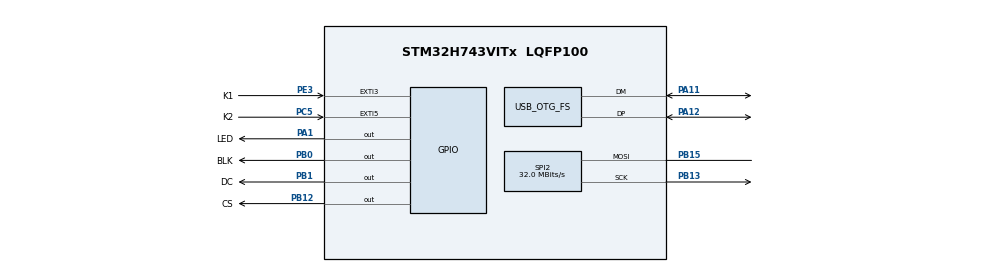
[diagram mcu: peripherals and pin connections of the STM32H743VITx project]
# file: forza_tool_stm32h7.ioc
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CORTEX_M7.AccessPermission_S-Cortex_Memory_Protection_Unit_Region1_Settings_S=MPU_REGION_FULL_ACCESS
CORTEX_M7.AccessPermission_S-Cortex_Memory_Protection_Unit_Region2_Settings_S=MPU_REGION_FULL_ACCESS
CORTEX_M7.AccessPermission_S-Cortex_Memory_Protection_Unit_Region3_Settings_S=MPU_REGION_FULL_ACCESS
CORTEX_M7.BaseAddress_S-Cortex_Memory_Protection_Unit_Region1_Settings_S=0x20000000
CORTEX_M7.BaseAddress_S-Cortex_Memory_Protection_Unit_Region2_Settings_S=0x24000000
CORTEX_M7.BaseAddress_S-Cortex_Memory_Protection_Unit_Region3_Settings_S=0x30000000
CORTEX_M7.CPU_DCache=Enabled
CORTEX_M7.CPU_ICache=Enabled
CORTEX_M7.DisableExec_S-Cortex_Memory_Protection_Unit_Region1_Settings_S=MPU_INSTRUCTION_ACCESS_ENABLE
CORTEX_M7.DisableExec_S-Cortex_Memory_Protection_Unit_Region2_Settings_S=MPU_INSTRUCTION_ACCESS_DISABLE
CORTEX_M7.DisableExec_S-Cortex_Memory_Protection_Unit_Region3_Settings_S=MPU_INSTRUCTION_ACCESS_DISABLE
CORTEX_M7.DisableExec_Spec=MPU_INSTRUCTION_ACCESS_DISABLE
CORTEX_M7.Enable_S-Cortex_Memory_Protection_Unit_Region1_Settings_S=MPU_REGION_ENABLE
CORTEX_M7.Enable_S-Cortex_Memory_Protection_Unit_Region2_Settings_S=MPU_REGION_ENABLE
CORTEX_M7.Enable_S-Cortex_Memory_Protection_Unit_Region3_Settings_S=MPU_REGION_ENABLE
CORTEX_M7.IsBufferable_S-Cortex_Memory_Protection_Unit_Region1_Settings_S=MPU_ACCESS_BUFFERABLE
CORTEX_M7.IsCacheable_S-Cortex_Memory_Protection_Unit_Region1_Settings_S=MPU_ACCESS_CACHEABLE
CORTEX_M7.IsShareable_S-Cortex_Memory_Protection_Unit_Region1_Settings_S=MPU_ACCESS_NOT_SHAREABLE
CORTEX_M7.IsShareable_S-Cortex_Memory_Protection_Unit_Region2_Settings_S=MPU_ACCESS_SHAREABLE
CORTEX_M7.IsShareable_S-Cortex_Memory_Protection_Unit_Region3_Settings_S=MPU_ACCESS_SHAREABLE
CORTEX_M7.IsShareable_Spec=MPU_ACCESS_SHAREABLE
CORTEX_M7.Size_S-Cortex_Memory_Protection_Unit_Region1_Settings_S=MPU_REGION_SIZE_128KB
CORTEX_M7.Size_S-Cortex_Memory_Protection_Unit_Region2_Settings_S=MPU_REGION_SIZE_512KB
CORTEX_M7.Size_S-Cortex_Memory_Protection_Unit_Region3_Settings_S=MPU_REGION_SIZE_512KB
CORTEX_M7.default_mode_Activation=1
Dma.Request0=SPI2_TX
Dma.SPI2_TX.0.Direction=DMA_MEMORY_TO_PERIPH
Dma.SPI2_TX.0.EventEnable=DISABLE
Dma.SPI2_TX.0.FIFOMode=DMA_FIFOMODE_DISABLE
Dma.SPI2_TX.0.Instance=DMA1_Stream0
Dma.SPI2_TX.0.MemDataAlignment=DMA_MDATAALIGN_BYTE
Dma.SPI2_TX.0.MemInc=DMA_MINC_ENABLE
Dma.SPI2_TX.0.Mode=DMA_NORMAL
Dma.SPI2_TX.0.PeriphDataAlignment=DMA_PDATAALIGN_BYTE
Dma.SPI2_TX.0.PeriphInc=DMA_PINC_DISABLE
Dma.SPI2_TX.0.Polarity=HAL_DMAMUX_REQ_GEN_RISING
Dma.SPI2_TX.0.Priority=DMA_PRIORITY_MEDIUM
Dma.SPI2_TX.0.RequestNumber=1
Dma.SPI2_TX.0.SignalID=NONE
Dma.SPI2_TX.0.SyncEnable=DISABLE
Dma.SPI2_TX.0.SyncPolarity=HAL_DMAMUX_SYNC_NO_EVENT
Dma.SPI2_TX.0.SyncRequestNumber=1
Dma.SPI2_TX.0.SyncSignalID=NONE
FREERTOS.Events01=displayReadyEvent,Dynamic,NULL;appEvent,Dynamic,NULL
FREERTOS.Queues01=spi2TxQueue,1,EventTask_t,0,Dynamic,NULL,NULL;defaultQueue,32,EventTask_t,0,Dynamic,NULL,NULL;spi2TxCompletedQueue,1,uint32_t,0,Dynamic,NULL,NULL
FREERTOS.Tasks01=defaultTask,24,4096,StartDefaultTask,Default,NULL,Static,defaultTaskBuffer,defaultTaskControlBlock;spi2TxTask,32,512,StartSpi2TxTask,As external,NULL,Static,spi2TxTaskBuffer,spi2TxTaskControlBlock
FREERTOS.Timers01=lvglTimer,lvglTimerCallback,osTimerPeriodic,As external,NULL,Dynamic,NULL;lwipTimer,lwipTimerCallback,osTimerPeriodic,As external,NULL,Dynamic,NULL;usbTimer,usbTimerCallback,osTimerOnce,As external,NULL,Dynamic,NULL;k1Timer,k1TimerCallback,osTimerOnce,As external,NULL,Dynamic,NULL;k2Timer,k2TimerCallback,osTimerOnce,As external,NULL,Dynamic,NULL;iwdgRefreshTimer,iwdgRefreshTimerCallback,osTimerPeriodic,As external,NULL,Dynamic,NULL
FREERTOS.configCHECK_FOR_STACK_OVERFLOW=2
FREERTOS.configENABLE_FPU=1
FREERTOS.configTIMER_TASK_STACK_DEPTH=1024
FREERTOS.configTOTAL_HEAP_SIZE=131072
FREERTOS.configUSE_NEWLIB_REENTRANT=1
IWDG1.Prescaler=IWDG_PRESCALER_32
IWDG1.Reload=1500
IWDG1.Window=1500
Mcu.Family=STM32H7
Mcu.Name=STM32H743VITx
Mcu.Package=LQFP100
NVIC.DMA1_Stream0_IRQn=true\:5\:0\:false\:false\:true\:true\:false\:true\:true
NVIC.EXTI3_IRQn=true\:5\:0\:false\:false\:true\:true\:true\:true\:true
NVIC.EXTI9_5_IRQn=true\:5\:0\:false\:false\:true\:true\:true\:true\:true
NVIC.OTG_FS_IRQn=true\:5\:0\:false\:false\:true\:true\:true\:true\:true
NVIC.PriorityGroup=NVIC_PRIORITYGROUP_4
NVIC.SPI2_IRQn=true\:5\:0\:false\:false\:true\:true\:false\:true\:true
NVIC.TIM6_DAC_IRQn=true\:15\:0\:false\:false\:true\:false\:false\:true\:true
NVIC.TimeBase=TIM6_DAC_IRQn
NVIC.TimeBaseIP=TIM6
PA1.GPIO_Label=LED
PA1.GPIO_Speed=GPIO_SPEED_FREQ_LOW
PA1.PinState=GPIO_PIN_SET
PA1.Signal=GPIO_Output
PA11.Mode=Device_Only
PA11.Signal=USB_OTG_FS_DM
PA12.Mode=Device_Only
PA12.Signal=USB_OTG_FS_DP
PA13\ (JTMS/SWDIO).Mode=Serial_Wire
PA13\ (JTMS/SWDIO).Signal=DEBUG_JTMS-SWDIO
PA14\ (JTCK/SWCLK).Mode=Serial_Wire
PA14\ (JTCK/SWCLK).Signal=DEBUG_JTCK-SWCLK
PB0.GPIO_Label=BLK
PB0.GPIO_Speed=GPIO_SPEED_FREQ_LOW
PB0.Signal=GPIO_Output
PB1.GPIO_Label=DC
PB1.GPIO_Speed=GPIO_SPEED_FREQ_LOW
PB1.Signal=GPIO_Output
PB12.GPIO_Label=CS
PB12.GPIO_Speed=GPIO_SPEED_FREQ_LOW
PB12.PinState=GPIO_PIN_SET
PB12.Signal=GPIO_Output
PB13.Mode=Simplex_Bidirectional_Master
PB13.Signal=SPI2_SCK
PB14.Signal=SPI2_MISO
PB15.Mode=Simplex_Bidirectional_Master
PB15.Signal=SPI2_MOSI
PC5.GPIO_Label=K2
PC5.GPIO_ModeDefaultEXTI=GPIO_MODE_IT_FALLING
PC5.GPIO_PuPd=GPIO_PULLUP
PC5.Signal=GPXTI5
PE3.GPIO_Label=K1
PE3.GPIO_ModeDefaultEXTI=GPIO_MODE_IT_FALLING
PE3.GPIO_PuPd=GPIO_PULLUP
PE3.Signal=GPXTI3
PH0-OSC_IN\ (PH0).Mode=HSE-External-Oscillator
PH0-OSC_IN\ (PH0).Signal=RCC_OSC_IN
PH1-OSC_OUT\ (PH1).Mode=HSE-External-Oscillator
PH1-OSC_OUT\ (PH1).Signal=RCC_OSC_OUT
ProjectManager.HeapSize=0x200
ProjectManager.StackSize=0x400
ProjectManager.TargetToolchain=CMake
RCC.ADCFreq_Value=50390625
RCC.APB1Freq_Value=112500000
RCC.APB2Freq_Value=112500000
RCC.APB3Freq_Value=112500000
RCC.APB4Freq_Value=112500000
RCC.CortexFreq_Value=225000000
RCC.D1PPRE=RCC_APB3_DIV2
RCC.D2PPRE1=RCC_APB1_DIV2
RCC.D2PPRE2=RCC_APB2_DIV2
RCC.D3PPRE=RCC_APB4_DIV2
RCC.DIVM1=2
RCC.DIVN1=36
RCC.DIVQ1=3
RCC.HCLKFreq_Value=225000000
RCC.PLL2FRACN=0
RCC.PLL3FRACN=0
RCC.PLLFRACN=0
RCC.PLLSourceVirtual=RCC_PLLSOURCE_HSE
RCC.SPI123CLockSelection=RCC_SPI123CLKSOURCE_CLKP
RCC.SYSCLKFreq_VALUE=225000000
RCC.SYSCLKSource=RCC_SYSCLKSOURCE_PLLCLK
RCC.USBCLockSelection=RCC_USBCLKSOURCE_HSI48
RCC.USBFreq_Value=48000000
SPI2.BaudRatePrescaler=SPI_BAUDRATEPRESCALER_2
SPI2.CLKPhase=SPI_PHASE_2EDGE
SPI2.CLKPolarity=SPI_POLARITY_HIGH
SPI2.CalculateBaudRate=32.0 MBits/s
SPI2.DataSize=SPI_DATASIZE_8BIT
SPI2.Direction=SPI_DIRECTION_1LINE
SPI2.Mode=SPI_MODE_MASTER
SPI2.VirtualType=VM_MASTER
USB_OTG_FS.VirtualMode=Device_Only
VP_FREERTOS_VS_CMSIS_V2.Mode=CMSIS_V2
VP_IWDG1_VS_IWDG.Mode=IWDG_Activate
VP_MEMORYMAP_VS_MEMORYMAP.Mode=CurAppReg
VP_SYS_VS_tim6.Mode=TIM6
board=custom

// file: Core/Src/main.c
/* USER CODE BEGIN Header */
/**
 ******************************************************************************
 * @file           : main.c
 * @brief          : Main program body
 ******************************************************************************
 * @attention
 *
 * Copyright (c) 2026 STMicroelectronics.
 * All rights reserved.
 *
 * This software is licensed under terms that can be found in the LICENSE file
 * in the root directory of this software component.
 * If no LICENSE file comes with this software, it is provided AS-IS.
 *
 ******************************************************************************
 */
/* USER CODE END Header */
#include "main.h"
#include "FreeRTOS.h"
#include "cmsis_os2.h"

/* USER CODE BEGIN Includes */
#include "app.h"
/* USER CODE END Includes */

typedef StaticTask_t osStaticThreadDef_t;

IWDG_HandleTypeDef hiwdg1;

SPI_HandleTypeDef hspi2;
DMA_HandleTypeDef hdma_spi2_tx;

PCD_HandleTypeDef hpcd_USB_OTG_FS;

/* Definitions for defaultTask */
osThreadId_t defaultTaskHandle;
uint32_t defaultTaskBuffer[ 4096 ];
osStaticThreadDef_t defaultTaskControlBlock;
const osThreadAttr_t defaultTask_attributes = {
  .name = "defaultTask",
  .cb_mem = &defaultTaskControlBlock,
  .cb_size = sizeof(defaultTaskControlBlock),
  .stack_mem = &defaultTaskBuffer[0],
  .stack_size = sizeof(defaultTaskBuffer),
  .priority = (osPriority_t) osPriorityNormal,
};
/* Definitions for spi2TxTask */
osThreadId_t spi2TxTaskHandle;
uint32_t spi2TxTaskBuffer[ 512 ];
osStaticThreadDef_t spi2TxTaskControlBlock;
const osThreadAttr_t spi2TxTask_attributes = {
  .name = "spi2TxTask",
  .cb_mem = &spi2TxTaskControlBlock,
  .cb_size = sizeof(spi2TxTaskControlBlock),
  .stack_mem = &spi2TxTaskBuffer[0],
  .stack_size = sizeof(spi2TxTaskBuffer),
  .priority = (osPriority_t) osPriorityAboveNormal,
};
/* Definitions for spi2TxQueue */
osMessageQueueId_t spi2TxQueueHandle;
const osMessageQueueAttr_t spi2TxQueue_attributes = {
  .name = "spi2TxQueue"
};
/* Definitions for defaultQueue */
osMessageQueueId_t defaultQueueHandle;
const osMessageQueueAttr_t defaultQueue_attributes = {
  .name = "defaultQueue"
};
/* Definitions for spi2TxCompletedQueue */
osMessageQueueId_t spi2TxCompletedQueueHandle;
const osMessageQueueAttr_t spi2TxCompletedQueue_attributes = {
  .name = "spi2TxCompletedQueue"
};
/* Definitions for lvglTimer */
osTimerId_t lvglTimerHandle;
const osTimerAttr_t lvglTimer_attributes = {
  .name = "lvglTimer"
};
/* Definitions for lwipTimer */
osTimerId_t lwipTimerHandle;
const osTimerAttr_t lwipTimer_attributes = {
  .name = "lwipTimer"
};
/* Definitions for usbTimer */
osTimerId_t usbTimerHandle;
const osTimerAttr_t usbTimer_attributes = {
  .name = "usbTimer"
};
/* Definitions for k1Timer */
osTimerId_t k1TimerHandle;
const osTimerAttr_t k1Timer_attributes = {
  .name = "k1Timer"
};
/* Definitions for k2Timer */
osTimerId_t k2TimerHandle;
const osTimerAttr_t k2Timer_attributes = {
  .name = "k2Timer"
};
/* Definitions for iwdgRefreshTimer */
osTimerId_t iwdgRefreshTimerHandle;
const osTimerAttr_t iwdgRefreshTimer_attributes = {
  .name = "iwdgRefreshTimer"
};
/* Definitions for displayReadyEvent */
osEventFlagsId_t displayReadyEventHandle;
const osEventFlagsAttr_t displayReadyEvent_attributes = {
  .name = "displayReadyEvent"
};
/* Definitions for appEvent */
osEventFlagsId_t appEventHandle;
const osEventFlagsAttr_t appEvent_attributes = {
  .name = "appEvent"
};

void SystemClock_Config(void);
void PeriphCommonClock_Config(void);
static void MPU_Config(void);
static void MX_GPIO_Init(void);
static void MX_DMA_Init(void);
static void MX_SPI2_Init(void);
static void MX_USB_OTG_FS_PCD_Init(void);
static void MX_IWDG1_Init(void);
void StartDefaultTask(void *argument);
extern void StartSpi2TxTask(void *argument);
extern void lvglTimerCallback(void *argument);
extern void lwipTimerCallback(void *argument);
extern void usbTimerCallback(void *argument);
extern void k1TimerCallback(void *argument);
extern void k2TimerCallback(void *argument);
extern void iwdgRefreshTimerCallback(void *argument);

int main(void)
{

  /* MPU Configuration--------------------------------------------------------*/
  MPU_Config();

  /* Enable the CPU Cache */

  /* Enable I-Cache---------------------------------------------------------*/
  SCB_EnableICache();

  /* Enable D-Cache---------------------------------------------------------*/
  SCB_EnableDCache();

  /* MCU Configuration--------------------------------------------------------*/

  /* Reset of all peripherals, Initializes the Flash interface and the Systick. */
  HAL_Init();

  /* Configure the system clock */
  SystemClock_Config();

  /* Configure the peripherals common clocks */
  PeriphCommonClock_Config();

  /* Initialize all configured peripherals */
  MX_GPIO_Init();
  MX_DMA_Init();
  MX_SPI2_Init();
  MX_USB_OTG_FS_PCD_Init();
  MX_IWDG1_Init();

  /* Init scheduler */
  osKernelInitialize();

  /* Create the timer(s) */
  /* creation of lvglTimer */
  lvglTimerHandle = osTimerNew(lvglTimerCallback, osTimerPeriodic, NULL, &lvglTimer_attributes);

  /* creation of lwipTimer */
  lwipTimerHandle = osTimerNew(lwipTimerCallback, osTimerPeriodic, NULL, &lwipTimer_attributes);

  /* creation of usbTimer */
  usbTimerHandle = osTimerNew(usbTimerCallback, osTimerOnce, NULL, &usbTimer_attributes);

  /* creation of k1Timer */
  k1TimerHandle = osTimerNew(k1TimerCallback, osTimerOnce, NULL, &k1Timer_attributes);

  /* creation of k2Timer */
  k2TimerHandle = osTimerNew(k2TimerCallback, osTimerOnce, NULL, &k2Timer_attributes);

  /* creation of iwdgRefreshTimer */
  iwdgRefreshTimerHandle = osTimerNew(iwdgRefreshTimerCallback, osTimerPeriodic, NULL, &iwdgRefreshTimer_attributes);

  /* Create the queue(s) */
  /* creation of spi2TxQueue */
  spi2TxQueueHandle = osMessageQueueNew (1, sizeof(EventTask_t), &spi2TxQueue_attributes);

  /* creation of defaultQueue */
  defaultQueueHandle = osMessageQueueNew (32, sizeof(EventTask_t), &defaultQueue_attributes);

  /* creation of spi2TxCompletedQueue */
  spi2TxCompletedQueueHandle = osMessageQueueNew (1, sizeof(uint32_t), &spi2TxCompletedQueue_attributes);

  /* Create the thread(s) */
  /* creation of defaultTask */
  defaultTaskHandle = osThreadNew(StartDefaultTask, NULL, &defaultTask_attributes);

  /* creation of spi2TxTask */
  spi2TxTaskHandle = osThreadNew(StartSpi2TxTask, NULL, &spi2TxTask_attributes);

  /* Create the event(s) */
  /* creation of displayReadyEvent */
  displayReadyEventHandle = osEventFlagsNew(&displayReadyEvent_attributes);

  /* creation of appEvent */
  appEventHandle = osEventFlagsNew(&appEvent_attributes);

  /* Start scheduler */
  osKernelStart();

  /* We should never get here as control is now taken by the scheduler */

  /* Infinite loop */
  while (1) {

  }
}

void SystemClock_Config(void)
{
  RCC_OscInitTypeDef RCC_OscInitStruct = {0};
  RCC_ClkInitTypeDef RCC_ClkInitStruct = {0};

  /** Supply configuration update enable
  */
  HAL_PWREx_ConfigSupply(PWR_LDO_SUPPLY);

  /** Configure the main internal regulator output voltage
  */
  __HAL_PWR_VOLTAGESCALING_CONFIG(PWR_REGULATOR_VOLTAGE_SCALE0);

  while(!__HAL_PWR_GET_FLAG(PWR_FLAG_VOSRDY)) {}

  /** Initializes the RCC Oscillators according to the specified parameters
  * in the RCC_OscInitTypeDef structure.
  */
  RCC_OscInitStruct.OscillatorType = RCC_OSCILLATORTYPE_HSI48|RCC_OSCILLATORTYPE_HSI
                              |RCC_OSCILLATORTYPE_LSI|RCC_OSCILLATORTYPE_HSE;
  RCC_OscInitStruct.HSEState = RCC_HSE_ON;
  RCC_OscInitStruct.HSIState = RCC_HSI_DIV1;
  RCC_OscInitStruct.HSICalibrationValue = RCC_HSICALIBRATION_DEFAULT;
  RCC_OscInitStruct.LSIState = RCC_LSI_ON;
  RCC_OscInitStruct.HSI48State = RCC_HSI48_ON;
  RCC_OscInitStruct.PLL.PLLState = RCC_PLL_ON;
  RCC_OscInitStruct.PLL.PLLSource = RCC_PLLSOURCE_HSE;
  RCC_OscInitStruct.PLL.PLLM = 2;
  RCC_OscInitStruct.PLL.PLLN = 36;
  RCC_OscInitStruct.PLL.PLLP = 2;
  RCC_OscInitStruct.PLL.PLLQ = 3;
  RCC_OscInitStruct.PLL.PLLR = 2;
  RCC_OscInitStruct.PLL.PLLRGE = RCC_PLL1VCIRANGE_3;
  RCC_OscInitStruct.PLL.PLLVCOSEL = RCC_PLL1VCOWIDE;
  RCC_OscInitStruct.PLL.PLLFRACN = 0;
  if (HAL_RCC_OscConfig(&RCC_OscInitStruct) != HAL_OK)
  {
    Error_Handler();
  }

  /** Initializes the CPU, AHB and APB buses clocks
  */
  RCC_ClkInitStruct.ClockType = RCC_CLOCKTYPE_HCLK|RCC_CLOCKTYPE_SYSCLK
                              |RCC_CLOCKTYPE_PCLK1|RCC_CLOCKTYPE_PCLK2
                              |RCC_CLOCKTYPE_D3PCLK1|RCC_CLOCKTYPE_D1PCLK1;
  RCC_ClkInitStruct.SYSCLKSource = RCC_SYSCLKSOURCE_PLLCLK;
  RCC_ClkInitStruct.SYSCLKDivider = RCC_SYSCLK_DIV1;
  RCC_ClkInitStruct.AHBCLKDivider = RCC_HCLK_DIV1;
  RCC_ClkInitStruct.APB3CLKDivider = RCC_APB3_DIV2;
  RCC_ClkInitStruct.APB1CLKDivider = RCC_APB1_DIV2;
  RCC_ClkInitStruct.APB2CLKDivider = RCC_APB2_DIV2;
  RCC_ClkInitStruct.APB4CLKDivider = RCC_APB4_DIV2;

  if (HAL_RCC_ClockConfig(&RCC_ClkInitStruct, FLASH_LATENCY_3) != HAL_OK)
  {
    Error_Handler();
  }
}

void PeriphCommonClock_Config(void)
{
  RCC_PeriphCLKInitTypeDef PeriphClkInitStruct = {0};

  /** Initializes the peripherals clock
  */
  PeriphClkInitStruct.PeriphClockSelection = RCC_PERIPHCLK_CKPER;
  PeriphClkInitStruct.CkperClockSelection = RCC_CLKPSOURCE_HSI;
  if (HAL_RCCEx_PeriphCLKConfig(&PeriphClkInitStruct) != HAL_OK)
  {
    Error_Handler();
  }
}

static void MX_IWDG1_Init(void)
{

  hiwdg1.Instance = IWDG1;
  hiwdg1.Init.Prescaler = IWDG_PRESCALER_32;
  hiwdg1.Init.Window = 2000;
  hiwdg1.Init.Reload = 2000;
  if (HAL_IWDG_Init(&hiwdg1) != HAL_OK)
  {
    Error_Handler();
  }

}

static void MX_SPI2_Init(void)
{

  /* SPI2 parameter configuration*/
  hspi2.Instance = SPI2;
  hspi2.Init.Mode = SPI_MODE_MASTER;
  hspi2.Init.Direction = SPI_DIRECTION_1LINE;
  hspi2.Init.DataSize = SPI_DATASIZE_8BIT;
  hspi2.Init.CLKPolarity = SPI_POLARITY_HIGH;
  hspi2.Init.CLKPhase = SPI_PHASE_2EDGE;
  hspi2.Init.NSS = SPI_NSS_SOFT;
  hspi2.Init.BaudRatePrescaler = SPI_BAUDRATEPRESCALER_2;
  hspi2.Init.FirstBit = SPI_FIRSTBIT_MSB;
  hspi2.Init.TIMode = SPI_TIMODE_DISABLE;
  hspi2.Init.CRCCalculation = SPI_CRCCALCULATION_DISABLE;
  hspi2.Init.CRCPolynomial = 0x0;
  hspi2.Init.NSSPMode = SPI_NSS_PULSE_ENABLE;
  hspi2.Init.NSSPolarity = SPI_NSS_POLARITY_LOW;
  hspi2.Init.FifoThreshold = SPI_FIFO_THRESHOLD_01DATA;
  hspi2.Init.TxCRCInitializationPattern = SPI_CRC_INITIALIZATION_ALL_ZERO_PATTERN;
  hspi2.Init.RxCRCInitializationPattern = SPI_CRC_INITIALIZATION_ALL_ZERO_PATTERN;
  hspi2.Init.MasterSSIdleness = SPI_MASTER_SS_IDLENESS_00CYCLE;
  hspi2.Init.MasterInterDataIdleness = SPI_MASTER_INTERDATA_IDLENESS_00CYCLE;
  hspi2.Init.MasterReceiverAutoSusp = SPI_MASTER_RX_AUTOSUSP_DISABLE;
  hspi2.Init.MasterKeepIOState = SPI_MASTER_KEEP_IO_STATE_DISABLE;
  hspi2.Init.IOSwap = SPI_IO_SWAP_DISABLE;
  if (HAL_SPI_Init(&hspi2) != HAL_OK)
  {
    Error_Handler();
  }

}

static void MX_USB_OTG_FS_PCD_Init(void)
{

  hpcd_USB_OTG_FS.Instance = USB_OTG_FS;
  hpcd_USB_OTG_FS.Init.dev_endpoints = 9;
  hpcd_USB_OTG_FS.Init.speed = PCD_SPEED_FULL;
  hpcd_USB_OTG_FS.Init.dma_enable = DISABLE;
  hpcd_USB_OTG_FS.Init.phy_itface = PCD_PHY_EMBEDDED;
  hpcd_USB_OTG_FS.Init.Sof_enable = DISABLE;
  hpcd_USB_OTG_FS.Init.low_power_enable = DISABLE;
  hpcd_USB_OTG_FS.Init.lpm_enable = DISABLE;
  hpcd_USB_OTG_FS.Init.battery_charging_enable = DISABLE;
  hpcd_USB_OTG_FS.Init.vbus_sensing_enable = DISABLE;
  hpcd_USB_OTG_FS.Init.use_dedicated_ep1 = DISABLE;
  if (HAL_PCD_Init(&hpcd_USB_OTG_FS) != HAL_OK)
  {
    Error_Handler();
  }

}

static void MX_DMA_Init(void)
{

  /* DMA controller clock enable */
  __HAL_RCC_DMA1_CLK_ENABLE();

  /* DMA interrupt init */
  /* DMA1_Stream0_IRQn interrupt configuration */
  HAL_NVIC_SetPriority(DMA1_Stream0_IRQn, 5, 0);
  HAL_NVIC_EnableIRQ(DMA1_Stream0_IRQn);

}

static void MX_GPIO_Init(void)
{
  GPIO_InitTypeDef GPIO_InitStruct = {0};

  /* GPIO Ports Clock Enable */
  __HAL_RCC_GPIOE_CLK_ENABLE();
  __HAL_RCC_GPIOC_CLK_ENABLE();
  __HAL_RCC_GPIOH_CLK_ENABLE();
  __HAL_RCC_GPIOA_CLK_ENABLE();
  __HAL_RCC_GPIOB_CLK_ENABLE();
  __HAL_RCC_GPIOD_CLK_ENABLE();

  /*Configure GPIO pin Output Level */
  HAL_GPIO_WritePin(LED_GPIO_Port, LED_Pin, GPIO_PIN_SET);

  /*Configure GPIO pin Output Level */
  HAL_GPIO_WritePin(GPIOB, BLK_Pin|DC_Pin, GPIO_PIN_RESET);

  /*Configure GPIO pin Output Level */
  HAL_GPIO_WritePin(CS_GPIO_Port, CS_Pin, GPIO_PIN_SET);

  /*Configure GPIO pins : PE2 PE4 PE5 PE6
                           PE7 PE8 PE9 PE10
                           PE11 PE12 PE13 PE14
                           PE15 PE0 PE1 */
  GPIO_InitStruct.Pin = GPIO_PIN_2|GPIO_PIN_4|GPIO_PIN_5|GPIO_PIN_6
                          |GPIO_PIN_7|GPIO_PIN_8|GPIO_PIN_9|GPIO_PIN_10
                          |GPIO_PIN_11|GPIO_PIN_12|GPIO_PIN_13|GPIO_PIN_14
                          |GPIO_PIN_15|GPIO_PIN_0|GPIO_PIN_1;
  GPIO_InitStruct.Mode = GPIO_MODE_ANALOG;
  GPIO_InitStruct.Pull = GPIO_NOPULL;
  HAL_GPIO_Init(GPIOE, &GPIO_InitStruct);

  /*Configure GPIO pin : K1_Pin */
  GPIO_InitStruct.Pin = K1_Pin;
  GPIO_InitStruct.Mode = GPIO_MODE_IT_FALLING;
  GPIO_InitStruct.Pull = GPIO_PULLUP;
  HAL_GPIO_Init(K1_GPIO_Port, &GPIO_InitStruct);

  /*Configure GPIO pins : PC13 PC14 PC15 PC0
                           PC1 PC2 PC3 PC4
                           PC6 PC7 PC8 PC9
                           PC10 PC11 PC12 */
  GPIO_InitStruct.Pin = GPIO_PIN_13|GPIO_PIN_14|GPIO_PIN_15|GPIO_PIN_0
                          |GPIO_PIN_1|GPIO_PIN_2|GPIO_PIN_3|GPIO_PIN_4
                          |GPIO_PIN_6|GPIO_PIN_7|GPIO_PIN_8|GPIO_PIN_9
                          |GPIO_PIN_10|GPIO_PIN_11|GPIO_PIN_12;
  GPIO_InitStruct.Mode = GPIO_MODE_ANALOG;
  GPIO_InitStruct.Pull = GPIO_NOPULL;
  HAL_GPIO_Init(GPIOC, &GPIO_InitStruct);

  /*Configure GPIO pins : PA0 PA2 PA3 PA4
                           PA5 PA6 PA7 PA8
                           PA9 PA10 PA15 */
  GPIO_InitStruct.Pin = GPIO_PIN_0|GPIO_PIN_2|GPIO_PIN_3|GPIO_PIN_4
                          |GPIO_PIN_5|GPIO_PIN_6|GPIO_PIN_7|GPIO_PIN_8
                          |GPIO_PIN_9|GPIO_PIN_10|GPIO_PIN_15;
  GPIO_InitStruct.Mode = GPIO_MODE_ANALOG;
  GPIO_InitStruct.Pull = GPIO_NOPULL;
  HAL_GPIO_Init(GPIOA, &GPIO_InitStruct);

  /*Configure GPIO pin : LED_Pin */
  GPIO_InitStruct.Pin = LED_Pin;
  GPIO_InitStruct.Mode = GPIO_MODE_OUTPUT_PP;
  GPIO_InitStruct.Pull = GPIO_NOPULL;
  GPIO_InitStruct.Speed = GPIO_SPEED_FREQ_LOW;
  HAL_GPIO_Init(LED_GPIO_Port, &GPIO_InitStruct);

  /*Configure GPIO pin : K2_Pin */
  GPIO_InitStruct.Pin = K2_Pin;
  GPIO_InitStruct.Mode = GPIO_MODE_IT_FALLING;
  GPIO_InitStruct.Pull = GPIO_PULLUP;
  HAL_GPIO_Init(K2_GPIO_Port, &GPIO_InitStruct);

  /*Configure GPIO pins : BLK_Pin DC_Pin CS_Pin */
  GPIO_InitStruct.Pin = BLK_Pin|DC_Pin|CS_Pin;
  GPIO_InitStruct.Mode = GPIO_MODE_OUTPUT_PP;
  GPIO_InitStruct.Pull = GPIO_NOPULL;
  GPIO_InitStruct.Speed = GPIO_SPEED_FREQ_LOW;
  HAL_GPIO_Init(GPIOB, &GPIO_InitStruct);

  /*Configure GPIO pins : PB2 PB10 PB11 PB3
                           PB4 PB5 PB6 PB7
                           PB8 PB9 */
  GPIO_InitStruct.Pin = GPIO_PIN_2|GPIO_PIN_10|GPIO_PIN_11|GPIO_PIN_3
                          |GPIO_PIN_4|GPIO_PIN_5|GPIO_PIN_6|GPIO_PIN_7
                          |GPIO_PIN_8|GPIO_PIN_9;
  GPIO_InitStruct.Mode = GPIO_MODE_ANALOG;
  GPIO_InitStruct.Pull = GPIO_NOPULL;
  HAL_GPIO_Init(GPIOB, &GPIO_InitStruct);

  /*Configure GPIO pins : PD8 PD9 PD10 PD11
                           PD12 PD13 PD14 PD15
                           PD0 PD1 PD2 PD3
                           PD4 PD5 PD6 PD7 */
  GPIO_InitStruct.Pin = GPIO_PIN_8|GPIO_PIN_9|GPIO_PIN_10|GPIO_PIN_11
                          |GPIO_PIN_12|GPIO_PIN_13|GPIO_PIN_14|GPIO_PIN_15
                          |GPIO_PIN_0|GPIO_PIN_1|GPIO_PIN_2|GPIO_PIN_3
                          |GPIO_PIN_4|GPIO_PIN_5|GPIO_PIN_6|GPIO_PIN_7;
  GPIO_InitStruct.Mode = GPIO_MODE_ANALOG;
  GPIO_InitStruct.Pull = GPIO_NOPULL;
  HAL_GPIO_Init(GPIOD, &GPIO_InitStruct);

  /*AnalogSwitch Config */
  HAL_SYSCFG_AnalogSwitchConfig(SYSCFG_SWITCH_PA1, SYSCFG_SWITCH_PA1_CLOSE);

  /* EXTI interrupt init*/
  HAL_NVIC_SetPriority(K1_EXTI_IRQn, 5, 0);
  HAL_NVIC_EnableIRQ(K1_EXTI_IRQn);

  HAL_NVIC_SetPriority(K2_EXTI_IRQn, 5, 0);
  HAL_NVIC_EnableIRQ(K2_EXTI_IRQn);

}

void StartDefaultTask(void *argument)
{
  /* USER CODE BEGIN 5 */
  AppContext_t context = {};
  run_app(&context);
  /* Infinite loop */
  for (;;) {
    osDelay(1);
  }
  /* USER CODE END 5 */
}

 /* MPU Configuration */

void MPU_Config(void)
{
  MPU_Region_InitTypeDef MPU_InitStruct = {0};

  /* Disables the MPU */
  HAL_MPU_Disable();

  /** Initializes and configures the Region and the memory to be protected
  */
  MPU_InitStruct.Enable = MPU_REGION_ENABLE;
  MPU_InitStruct.Number = MPU_REGION_NUMBER0;
  MPU_InitStruct.BaseAddress = 0x0;
  MPU_InitStruct.Size = MPU_REGION_SIZE_4GB;
  MPU_InitStruct.SubRegionDisable = 0x87;
  MPU_InitStruct.TypeExtField = MPU_TEX_LEVEL0;
  MPU_InitStruct.AccessPermission = MPU_REGION_NO_ACCESS;
  MPU_InitStruct.DisableExec = MPU_INSTRUCTION_ACCESS_DISABLE;
  MPU_InitStruct.IsShareable = MPU_ACCESS_SHAREABLE;
  MPU_InitStruct.IsCacheable = MPU_ACCESS_NOT_CACHEABLE;
  MPU_InitStruct.IsBufferable = MPU_ACCESS_NOT_BUFFERABLE;

  HAL_MPU_ConfigRegion(&MPU_InitStruct);

  /** Initializes and configures the Region and the memory to be protected
  */
  MPU_InitStruct.Number = MPU_REGION_NUMBER1;
  MPU_InitStruct.BaseAddress = 0x20000000;
  MPU_InitStruct.Size = MPU_REGION_SIZE_128KB;
  MPU_InitStruct.SubRegionDisable = 0x0;
  MPU_InitStruct.AccessPermission = MPU_REGION_FULL_ACCESS;
  MPU_InitStruct.DisableExec = MPU_INSTRUCTION_ACCESS_ENABLE;
  MPU_InitStruct.IsShareable = MPU_ACCESS_NOT_SHAREABLE;
  MPU_InitStruct.IsCacheable = MPU_ACCESS_CACHEABLE;
  MPU_InitStruct.IsBufferable = MPU_ACCESS_BUFFERABLE;

  HAL_MPU_ConfigRegion(&MPU_InitStruct);

  /** Initializes and configures the Region and the memory to be protected
  */
  MPU_InitStruct.Number = MPU_REGION_NUMBER2;
  MPU_InitStruct.BaseAddress = 0x24000000;
  MPU_InitStruct.Size = MPU_REGION_SIZE_512KB;
  MPU_InitStruct.DisableExec = MPU_INSTRUCTION_ACCESS_DISABLE;
  MPU_InitStruct.IsShareable = MPU_ACCESS_SHAREABLE;
  MPU_InitStruct.IsCacheable = MPU_ACCESS_NOT_CACHEABLE;
  MPU_InitStruct.IsBufferable = MPU_ACCESS_NOT_BUFFERABLE;

  HAL_MPU_ConfigRegion(&MPU_InitStruct);

  /** Initializes and configures the Region and the memory to be protected
  */
  MPU_InitStruct.Number = MPU_REGION_NUMBER3;
  MPU_InitStruct.BaseAddress = 0x30000000;

  HAL_MPU_ConfigRegion(&MPU_InitStruct);
  /* Enables the MPU */
  HAL_MPU_Enable(MPU_PRIVILEGED_DEFAULT);

}

void HAL_TIM_PeriodElapsedCallback(TIM_HandleTypeDef *htim)
{
  if (htim->Instance == TIM6)
  {
    HAL_IncTick();
  }
}

void Error_Handler(void)
{
  __disable_irq();
  while (1) {
  }
}
#ifdef USE_FULL_ASSERT
/**
  * @brief  Reports the name of the source file and the source line number
  *         where the assert_param error has occurred.
  * @param  file: pointer to the source file name
  * @param  line: assert_param error line source number
  * @retval None
  */
void assert_failed(uint8_t *file, uint32_t line)
{
  /* USER CODE BEGIN 6 */
  /* User can add his own implementation to report the file name and line
     number, ex: printf("Wrong parameters value: file %s on line %d\r\n", file,
     line) */
  /* USER CODE END 6 */
}
#endif /* USE_FULL_ASSERT */
